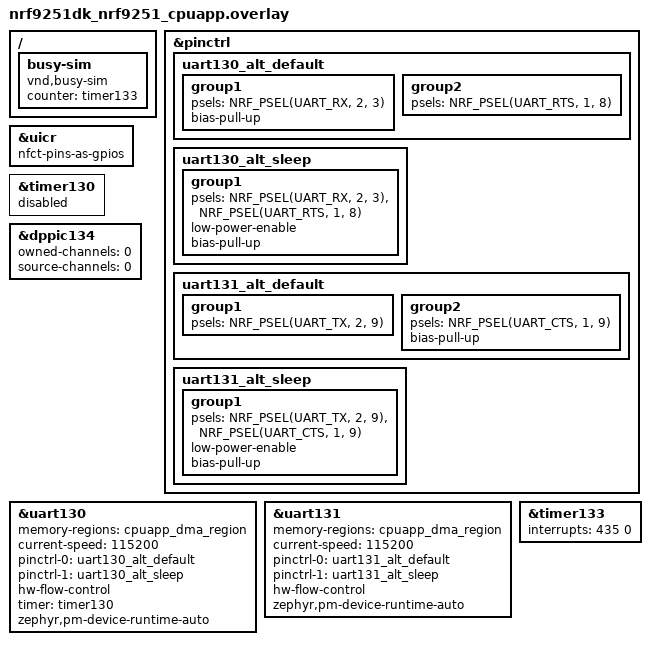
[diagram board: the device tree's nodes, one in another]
/*
 * Copyright (c) 2026 Nordic Semiconductor ASA
 *
 * SPDX-License-Identifier: LicenseRef-Nordic-5-Clause
 */

/* Test requires loopbacks:
 * TX-RX: P2.03 - P2.09
 * RTS-CTS: P1.08 - P1.09 (connected with NFCT antena)
 */

&pinctrl {
	uart130_alt_default: uart130_alt_default {
		group1 {
			psels = <NRF_PSEL(UART_RX, 2, 3)>;
			bias-pull-up;
		};

		group2 {
			psels = <NRF_PSEL(UART_RTS, 1, 8)>;
		};
	};

	uart130_alt_sleep: uart130_alt_sleep {
		group1 {
			psels = <NRF_PSEL(UART_RX, 2, 3)>,
				<NRF_PSEL(UART_RTS, 1, 8)>;
			low-power-enable;
			bias-pull-up;
		};
	};

	uart131_alt_default: uart131_alt_default {
		group1 {
			psels = <NRF_PSEL(UART_TX, 2, 9)>;
		};

		group2 {
			psels = <NRF_PSEL(UART_CTS, 1, 9)>;
			bias-pull-up;
		};
	};

	uart131_alt_sleep: uart131_alt_sleep {
		group1 {
			psels = <NRF_PSEL(UART_TX, 2, 9)>,
				<NRF_PSEL(UART_CTS, 1, 9)>;
			low-power-enable;
			bias-pull-up;
		};
	};
};

&uicr {
	nfct-pins-as-gpios;
};

&timer130 {
	status = "reserved";
};

&dppic134 {
	owned-channels = <0>;
	source-channels = <0>;
	status = "okay";
};

dut: &uart130 {
	status = "okay";
	memory-regions = <&cpuapp_dma_region>;
	current-speed = <115200>;
	pinctrl-0 = <&uart130_alt_default>;
	pinctrl-1 = <&uart130_alt_sleep>;
	pinctrl-names = "default", "sleep";
	hw-flow-control;
	timer = <&timer130>;
	zephyr,pm-device-runtime-auto;
};

dut_aux: &uart131 {
	status = "okay";
	memory-regions = <&cpuapp_dma_region>;
	current-speed = <115200>;
	pinctrl-0 = <&uart131_alt_default>;
	pinctrl-1 = <&uart131_alt_sleep>;
	pinctrl-names = "default", "sleep";
	hw-flow-control;
	zephyr,pm-device-runtime-auto;
};

&timer133 {
	status = "okay";
	interrupts = <435 0>;
};

/ {
	busy-sim {
		compatible = "vnd,busy-sim";
		status = "okay";
		counter = <&timer133>;
	};
};
